# Cortex_M33 register map
Vendor: ARM Ltd.; File version: 1.3
Cortex-M33 core descriptions, generated from ARM develloper studio
CPU: CM33 r0p0, little endian, MPU, no FPU, vendor SysTick, 8 interrupt priority bits
Registers are 32-bit, read-write, no defined reset value unless marked. A register's access mark holds for its fields unless they carry their own. Offsets are from the block's base; lines under a group give offsets from that group; [hi:lo] are bit positions; {n}, {i} and the like mark numbered series; 'fields as' and 'values as' point back to an identical list; <NAME> marks a mode.

## Memory map
0xE000E004 ICB size 0x60 — Interrupt Control Registers
0xE000E004 NVIC size 0x205DC — Nested Vectored Interrupt Controller registers
0xE000E010 SYST size 0x180 — SysTick Control Registers
0xE000ED00 SCB size 0x890 — System Control Block
0xE000ED90 MPU size 0x7E0 — Memory protection Unit Control Registers
0xE000EDD0 SAU size 0xE0 — Security Attribute Unit
0xE000EDF0 DCB size 0xC0 — Debug Registers
0xE000EF00 SIG size 0x20 — Software Interrupt Control
0xE000EF34 FPE size 0x180 — Floating Point Control Registers
0xE000EF50 CM size 0x140 — Cache Maintenance Operations
0xE000EFB0 DIB size 0x220 — Identification Registers

## CM — Cache Maintenance Operations
Base 0xE000EF50
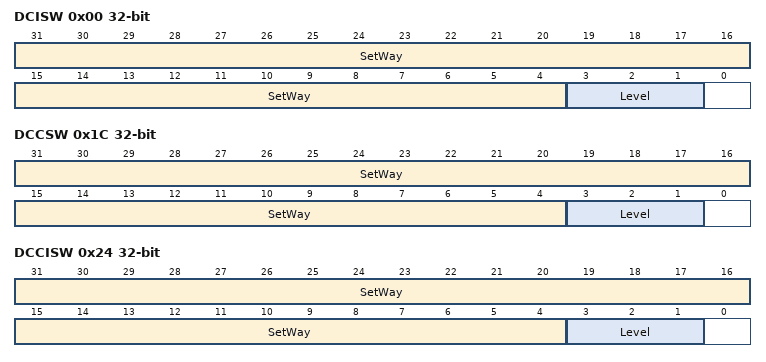
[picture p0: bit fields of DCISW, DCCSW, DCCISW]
0x00 DCISW wo
  [31:4] SetWay, [3:1] Level
0x00 ICIALLU wo
  [31:0] Ignored
0x08 ICIMVAU wo
  [31:0] ADDRESS
0x0C DCIMVAC wo
  [31:0] ADDRESS
0x14 DCCMVAU wo
  [31:0] ADDRESS
0x18 DCCMVAC wo
  [31:0] ADDRESS
0x1C DCCSW wo
  [31:4] SetWay, [3:1] Level
0x20 DCCIMVAC wo
  [31:0] ADDRESS
0x24 DCCISW wo
  [31:4] SetWay, [3:1] Level
0x28 BPIALL wo
  [31:0] Ignored

## DCB — Debug Registers
Base 0xE000EDF0
0x00 DHCSR
  [26] S_RESTART_ST
  [25] S_RESET_ST
  [24] S_RETIRE_ST
  [20] S_SDE
  [19] S_LOCKUP
  [18] S_SLEEP
  [17] S_HALT
  [31:16] DBGKEY — Debug key
  [16] S_REGRDY
  [5] C_SNAPSTALL
  [3] C_MASKINTS
  [2] C_STEP
  [1] C_HALT
  [0] C_DEBUGEN
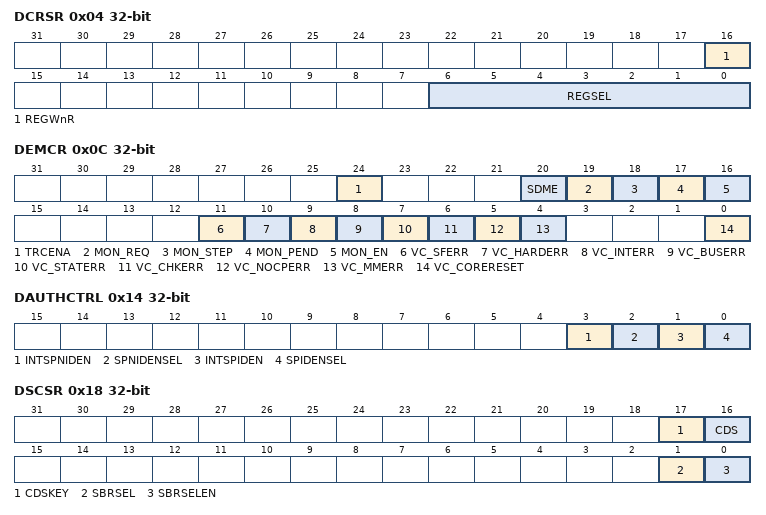
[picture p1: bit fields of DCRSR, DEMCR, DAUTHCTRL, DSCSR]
0x04 DCRSR wo
  [16] REGWnR, [6:0] REGSEL
0x08 DCRDR
  [31:0] DBGTMP
0x0C DEMCR ro
  [24] TRCENA, [20] SDME, [19] MON_REQ, [18] MON_STEP, [17] MON_PEND, [16] MON_EN, [11] VC_SFERR, [10] VC_HARDERR, [9] VC_INTERR, [8] VC_BUSERR, [7] VC_STATERR, [6] VC_CHKERR, [5] VC_NOCPERR, [4] VC_MMERR, [0] VC_CORERESET
0x14 DAUTHCTRL
  [3] INTSPNIDEN, [2] SPNIDENSEL, [1] INTSPIDEN, [0] SPIDENSEL
0x18 DSCSR ro
  [17] CDSKEY, [16] CDS, [1] SBRSEL, [0] SBRSELEN

## DIB — Identification Registers
Base 0xE000EFB0
0x00 DLAR wo
  [31:0] KEY
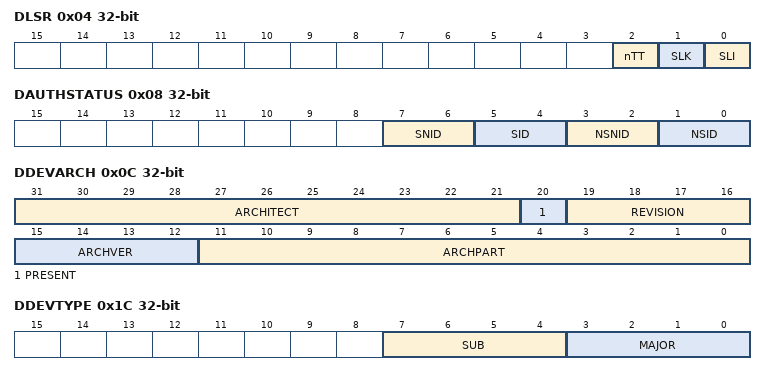
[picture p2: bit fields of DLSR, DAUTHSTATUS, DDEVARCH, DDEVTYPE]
0x04 DLSR ro
  [2] nTT, [1] SLK, [0] SLI
0x08 DAUTHSTATUS ro
  [7:6] SNID, [5:4] SID, [3:2] NSNID, [1:0] NSID
0x0C DDEVARCH ro
  [31:21] ARCHITECT, [20] PRESENT, [19:16] REVISION, [15:12] ARCHVER, [11:0] ARCHPART
0x1C DDEVTYPE ro
  [7:4] SUB — Sub-type
  [3:0] MAJOR
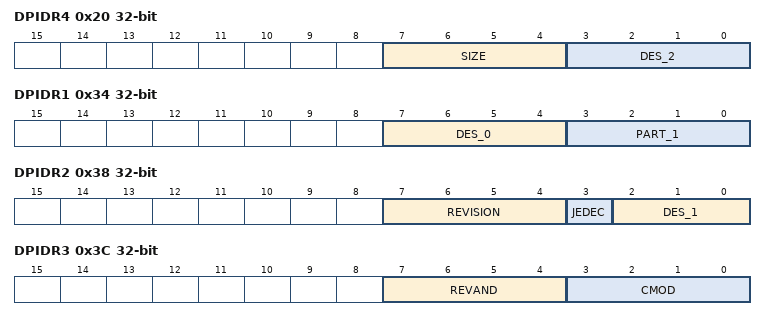
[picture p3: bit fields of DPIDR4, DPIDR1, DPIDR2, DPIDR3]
0x20 DPIDR4 ro
  [7:4] SIZE — 4KB count
  [3:0] DES_2
{0x10+4i} DPIDR{i} ro (i=5..7)
0x30 DPIDR0 ro
  [7:0] PART_0
0x34 DPIDR1 ro
  [7:4] DES_0, [3:0] PART_1
0x38 DPIDR2 ro
  [7:4] REVISION, [3] JEDEC, [2:0] DES_1
0x3C DPIDR3 ro
  [7:4] REVAND, [3:0] CMOD
0x40 DCIDR0 ro
  [7:0] PRMBL_0
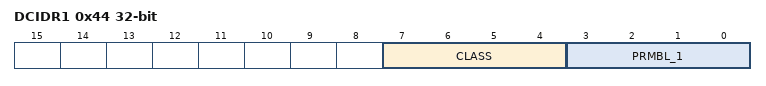
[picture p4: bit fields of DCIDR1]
0x44 DCIDR1 ro
  [7:4] CLASS, [3:0] PRMBL_1
0x48 DCIDR2 ro
  [7:0] PRMBL_2
0x4C DCIDR3 ro
  [7:0] PRMBL_3

## FPE — Floating Point Control Registers
Base 0xE000EF34
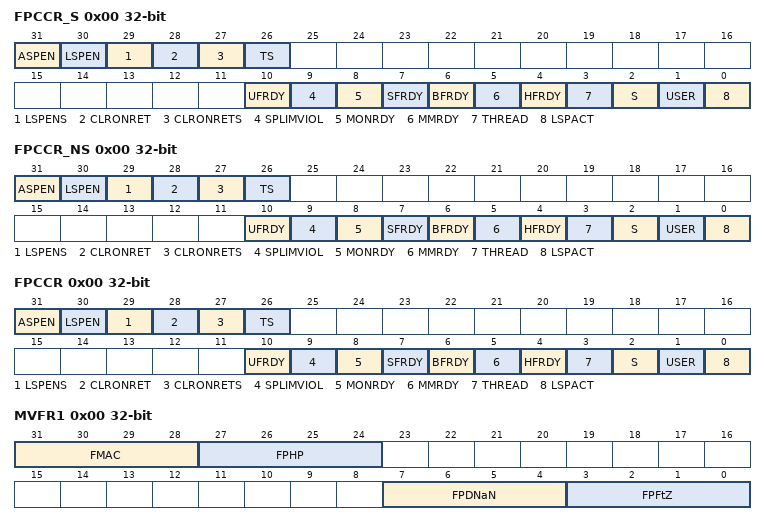
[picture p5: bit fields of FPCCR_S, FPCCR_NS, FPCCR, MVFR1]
0x00 FPCCR_S
  [31] ASPEN, [30] LSPEN, [29] LSPENS, [28] CLRONRET, [27] CLRONRETS, [26] TS, [10] UFRDY, [9] SPLIMVIOL, [8] MONRDY, [7] SFRDY, [6] BFRDY, [5] MMRDY, [4] HFRDY, [3] THREAD, [2] S, [1] USER, [0] LSPACT
0x00 FPCCR_NS
  fields as FPCCR_S
0x00 FPCCR
  fields as FPCCR_S
0x00 MVFR1 ro
  [31:28] FMAC, [27:24] FPHP, [7:4] FPDNaN, [3:0] FPFtZ
0x04 FPCAR_S
  [31:3] ADDRESS
0x04 FPCAR_NS
  [31:3] ADDRESS
0x04 FPCAR
  [31:3] ADDRESS
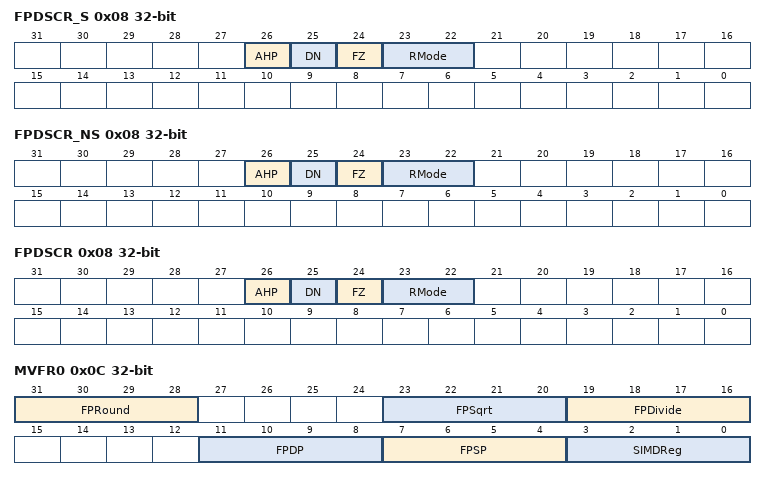
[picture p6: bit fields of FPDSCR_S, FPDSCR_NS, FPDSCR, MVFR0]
0x08 FPDSCR_S
  [26] AHP, [25] DN, [24] FZ, [23:22] RMode
0x08 FPDSCR_NS
  [26] AHP, [25] DN, [24] FZ, [23:22] RMode
0x08 FPDSCR
  [26] AHP, [25] DN, [24] FZ, [23:22] RMode
0x0C MVFR0 ro
  [31:28] FPRound, [23:20] FPSqrt, [19:16] FPDivide, [11:8] FPDP, [7:4] FPSP, [3:0] SIMDReg
0x14 MVFR2 ro
  [7:4] FPMisc

## Notices in the file
Copyright (c) 2021 STMicroelectronics.
SPDX-License-Identifier: Apache-2.0
Licensed under the Apache License, Version 2.0 (the "License");
you may not use this file except in compliance with the License.
You may obtain a copy of the License at
http://www.apache.org/licenses/LICENSE-2.0
Unless required by applicable law or agreed to in writing, software
distributed under the License is distributed on an "AS IS" BASIS,
WITHOUT WARRANTIES OR CONDITIONS OF ANY KIND, either express or implied.
See the License for the specific language governing permissions and
limitations under the License.
